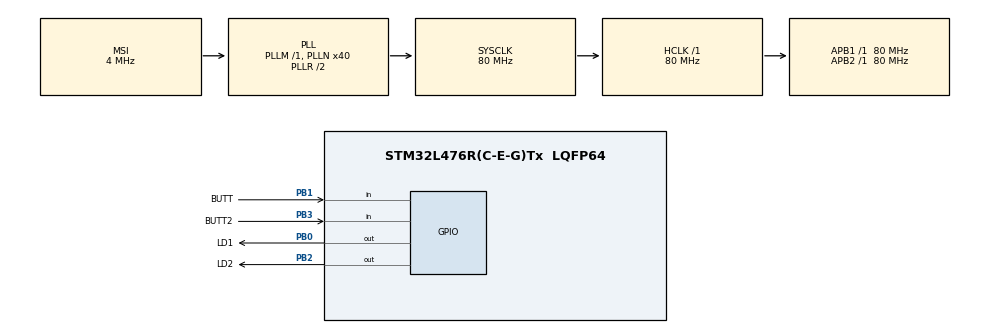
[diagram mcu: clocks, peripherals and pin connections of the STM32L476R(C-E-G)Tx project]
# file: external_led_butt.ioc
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Mcu.Family=STM32L4
Mcu.Name=STM32L476R(C-E-G)Tx
Mcu.Package=LQFP64
NVIC.PriorityGroup=NVIC_PRIORITYGROUP_4
PB0.GPIO_Label=LD1
PB0.Signal=GPIO_Output
PB1.GPIO_Label=BUTT
PB1.GPIO_PuPd=GPIO_PULLUP
PB1.Signal=GPIO_Input
PB2.GPIO_Label=LD2
PB2.Signal=GPIO_Output
PB3\ (JTDO-TRACESWO).GPIO_Label=BUTT2
PB3\ (JTDO-TRACESWO).GPIO_PuPd=GPIO_PULLUP
PB3\ (JTDO-TRACESWO).Signal=GPIO_Input
PH0-OSC_IN\ (PH0).Mode=HSE-External-Oscillator
PH0-OSC_IN\ (PH0).Signal=RCC_OSC_IN
PH1-OSC_OUT\ (PH1).Mode=HSE-External-Oscillator
PH1-OSC_OUT\ (PH1).Signal=RCC_OSC_OUT
ProjectManager.HeapSize=0x200
ProjectManager.StackSize=0x400
ProjectManager.TargetToolchain=STM32CubeIDE
RCC.AHBFreq_Value=80000000
RCC.APB1Freq_Value=80000000
RCC.APB1TimFreq_Value=80000000
RCC.APB2Freq_Value=80000000
RCC.APB2TimFreq_Value=80000000
RCC.CortexFreq_Value=80000000
RCC.HCLKFreq_Value=80000000
RCC.HSE_VALUE=8000000
RCC.HSI_VALUE=16000000
RCC.LSE_VALUE=32768
RCC.MSI_VALUE=4000000
RCC.PLLN=40
RCC.SYSCLKFreq_VALUE=80000000
RCC.SYSCLKSource=RCC_SYSCLKSOURCE_PLLCLK
RCC.VCOOutputFreq_Value=160000000
board=custom

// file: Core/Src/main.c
/* USER CODE BEGIN Header */
/**
  ******************************************************************************
  * @file           : main.c
  * @brief          : Main program body
  ******************************************************************************
  * @attention
  *
  * Copyright (c) 2025 STMicroelectronics.
  * All rights reserved.
  *
  * This software is licensed under terms that can be found in the LICENSE file
  * in the root directory of this software component.
  * If no LICENSE file comes with this software, it is provided AS-IS.
  *
  ******************************************************************************
  */
/* USER CODE END Header */
#include "main.h"

/* USER CODE BEGIN PV */
uint8_t butt1State = 0;       // Current state of BUTT1
uint8_t lastButt1State = 0;   // Last state of BUTT1 for edge detection
uint8_t butt2State = 0;       // Current state of BUTT2

/* USER CODE END PV */

void SystemClock_Config(void);
static void MX_GPIO_Init(void);

int main(void)
{

  /* MCU Configuration--------------------------------------------------------*/

  /* Reset of all peripherals, Initializes the Flash interface and the Systick. */
  HAL_Init();

  /* Configure the system clock */
  SystemClock_Config();

  /* Initialize all configured peripherals */
  MX_GPIO_Init();

  /* Infinite loop */
  while (1)
  {
	  butt1State = HAL_GPIO_ReadPin(GPIOB, GPIO_PIN_1); // BUTT1
	      butt2State = HAL_GPIO_ReadPin(GPIOB, GPIO_PIN_3); // BUTT2

	      // BUTT1: Toggle LED1 on press (falling edge)
	      if (butt1State == 0 && lastButt1State == 1) // Button pressed
	      {
	        HAL_GPIO_TogglePin(GPIOB, GPIO_PIN_0); // Toggle LED1
	        HAL_Delay(50); // Debounce delay
	      }
	      lastButt1State = butt1State; // Update last state

	      // BUTT2: LED2 ON while pressed, OFF when released
	      if (butt2State == 0) // Button pressed
	      {
	        HAL_GPIO_WritePin(GPIOB, GPIO_PIN_2, GPIO_PIN_SET); // LED2 ON
	      }
	      else // Button released
	      {
	        HAL_GPIO_WritePin(GPIOB, GPIO_PIN_2, GPIO_PIN_RESET); // LED2 OFF
	      }

  }
}

void SystemClock_Config(void)
{
  RCC_OscInitTypeDef RCC_OscInitStruct = {0};
  RCC_ClkInitTypeDef RCC_ClkInitStruct = {0};

  /** Configure the main internal regulator output voltage
  */
  if (HAL_PWREx_ControlVoltageScaling(PWR_REGULATOR_VOLTAGE_SCALE1) != HAL_OK)
  {
    Error_Handler();
  }

  /** Initializes the RCC Oscillators according to the specified parameters
  * in the RCC_OscInitTypeDef structure.
  */
  RCC_OscInitStruct.OscillatorType = RCC_OSCILLATORTYPE_MSI;
  RCC_OscInitStruct.MSIState = RCC_MSI_ON;
  RCC_OscInitStruct.MSICalibrationValue = 0;
  RCC_OscInitStruct.MSIClockRange = RCC_MSIRANGE_6;
  RCC_OscInitStruct.PLL.PLLState = RCC_PLL_ON;
  RCC_OscInitStruct.PLL.PLLSource = RCC_PLLSOURCE_MSI;
  RCC_OscInitStruct.PLL.PLLM = 1;
  RCC_OscInitStruct.PLL.PLLN = 40;
  RCC_OscInitStruct.PLL.PLLP = RCC_PLLP_DIV7;
  RCC_OscInitStruct.PLL.PLLQ = RCC_PLLQ_DIV2;
  RCC_OscInitStruct.PLL.PLLR = RCC_PLLR_DIV2;
  if (HAL_RCC_OscConfig(&RCC_OscInitStruct) != HAL_OK)
  {
    Error_Handler();
  }

  /** Initializes the CPU, AHB and APB buses clocks
  */
  RCC_ClkInitStruct.ClockType = RCC_CLOCKTYPE_HCLK|RCC_CLOCKTYPE_SYSCLK
                              |RCC_CLOCKTYPE_PCLK1|RCC_CLOCKTYPE_PCLK2;
  RCC_ClkInitStruct.SYSCLKSource = RCC_SYSCLKSOURCE_PLLCLK;
  RCC_ClkInitStruct.AHBCLKDivider = RCC_SYSCLK_DIV1;
  RCC_ClkInitStruct.APB1CLKDivider = RCC_HCLK_DIV1;
  RCC_ClkInitStruct.APB2CLKDivider = RCC_HCLK_DIV1;

  if (HAL_RCC_ClockConfig(&RCC_ClkInitStruct, FLASH_LATENCY_4) != HAL_OK)
  {
    Error_Handler();
  }
}

static void MX_GPIO_Init(void)
{
  GPIO_InitTypeDef GPIO_InitStruct = {0};

  /* GPIO Ports Clock Enable */
  __HAL_RCC_GPIOH_CLK_ENABLE();
  __HAL_RCC_GPIOB_CLK_ENABLE();

  /*Configure GPIO pin Output Level */
  HAL_GPIO_WritePin(GPIOB, LD1_Pin|LD2_Pin, GPIO_PIN_RESET);

  /*Configure GPIO pins : LD1_Pin LD2_Pin */
  GPIO_InitStruct.Pin = LD1_Pin|LD2_Pin;
  GPIO_InitStruct.Mode = GPIO_MODE_OUTPUT_PP;
  GPIO_InitStruct.Pull = GPIO_NOPULL;
  GPIO_InitStruct.Speed = GPIO_SPEED_FREQ_LOW;
  HAL_GPIO_Init(GPIOB, &GPIO_InitStruct);

  /*Configure GPIO pins : BUTT_Pin BUTT2_Pin */
  GPIO_InitStruct.Pin = BUTT_Pin|BUTT2_Pin;
  GPIO_InitStruct.Mode = GPIO_MODE_INPUT;
  GPIO_InitStruct.Pull = GPIO_PULLUP;
  HAL_GPIO_Init(GPIOB, &GPIO_InitStruct);

}

void Error_Handler(void)
{
  __disable_irq();
  while (1)
  {
  }
}
